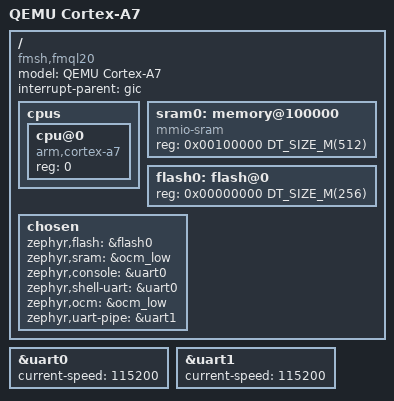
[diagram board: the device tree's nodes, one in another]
/*
 * Copyright (c) 2024 SYSTech Co.
 * SPDX-License-Identifier: Apache-2.0
 */

/dts-v1/;

#include <freq.h>
#include <fmsh/fmql_psoc.dtsi>

/ {
	model = "QEMU Cortex-A7";
	compatible = "fmsh,fmql20", "arm,cortex-a7";
	interrupt-parent = <&gic>;

	cpus {
		#address-cells = <1>;
		#size-cells = <0>;

		cpu@0 {
			device_type = "cpu";
			compatible = "arm,cortex-a7";
			reg = <0>;
		};
	};

	sram0: memory@100000 {
		compatible = "mmio-sram";
		reg = <0x00100000 DT_SIZE_M(512)>;
	};

	flash0: flash@0 {
		reg = <0x00000000 DT_SIZE_M(256)>;
	};

	chosen {
		zephyr,flash      = &flash0;
		zephyr,sram       = &ocm_low;
		zephyr,console    = &uart0;
		zephyr,shell-uart = &uart0;
		zephyr,ocm        = &ocm_low;
		zephyr,uart-pipe  = &uart1;
	};
};

&uart0 {
	status = "okay";
	current-speed = <115200>;
};

&uart1 {
	status = "okay";
	current-speed = <115200>;
};

